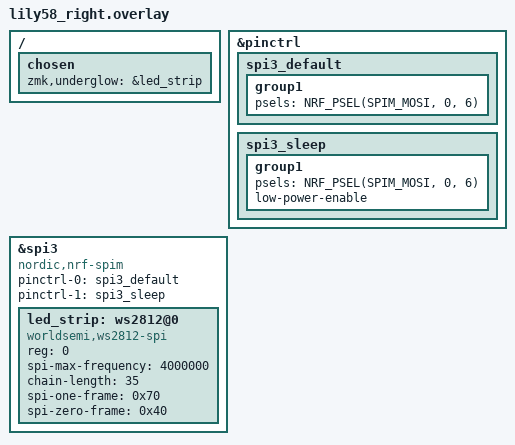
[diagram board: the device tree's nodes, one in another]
/*
 * Copyright (c) 2024 The ZMK Contributors
 *
 * SPDX-License-Identifier: MIT
 */

#include <dt-bindings/pinctrl/nrf-pinctrl.h>

&pinctrl {
	spi3_default: spi3_default {
		group1 {
			psels = <NRF_PSEL(SPIM_MOSI, 0, 6)>;
		};
	};

	spi3_sleep: spi3_sleep {
		group1 {
			psels = <NRF_PSEL(SPIM_MOSI, 0, 6)>;
			low-power-enable;
		};
	};
};

&spi3 {
	compatible = "nordic,nrf-spim";
	status = "okay";
	pinctrl-0 = <&spi3_default>;
	pinctrl-1 = <&spi3_sleep>;
	pinctrl-names = "default", "sleep";

	led_strip: ws2812@0 {
		compatible = "worldsemi,ws2812-spi";
		reg = <0>;
		spi-max-frequency = <4000000>;
		/* 29 per-key LEDs + 6 underglow LEDs on this half */
		chain-length = <35>;
		spi-one-frame = <0x70>;
		spi-zero-frame = <0x40>;
	};
};

/ {
	chosen {
		zmk,underglow = &led_strip;
	};
};
